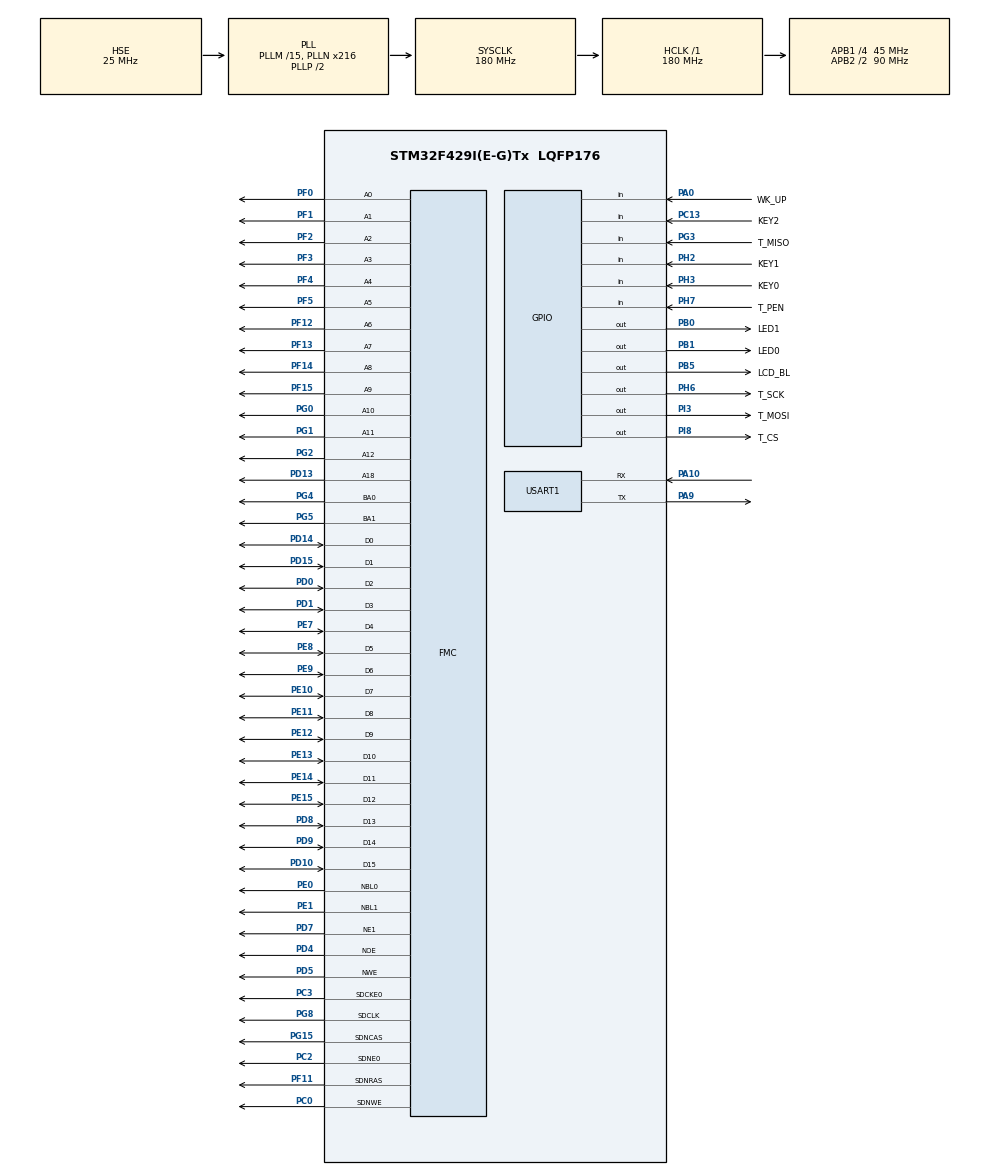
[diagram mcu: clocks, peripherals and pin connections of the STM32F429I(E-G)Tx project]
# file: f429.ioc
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FMC.BusTurnAroundDuration1=0
FMC.CASLatency1=FMC_SDRAM_CAS_LATENCY_3
FMC.ColumnBitsNumber1=FMC_SDRAM_COLUMN_BITS_NUM_9
FMC.DataSetupTime1=70
FMC.ExitSelfRefreshDelay1=8
FMC.ExtendedBusTurnAroundDuration1=0
FMC.ExtendedDataSetupTime1=15
FMC.ExtendedMode1=FMC_EXTENDED_MODE_ENABLE
FMC.LoadToActiveDelay1=2
FMC.RCDDelay1=2
FMC.RPDelay1=2
FMC.RPDelay2=2
FMC.ReadBurst1=FMC_SDRAM_RBURST_ENABLE
FMC.ReadBurst2=FMC_SDRAM_RBURST_ENABLE
FMC.ReadPipeDelay1=FMC_SDRAM_RPIPE_DELAY_1
FMC.ReadPipeDelay2=FMC_SDRAM_RPIPE_DELAY_1
FMC.RowCycleDelay1=6
FMC.RowCycleDelay2=6
FMC.SDClockPeriod1=FMC_SDRAM_CLOCK_PERIOD_2
FMC.SDClockPeriod2=FMC_SDRAM_CLOCK_PERIOD_2
FMC.SelfRefreshTime1=6
FMC.WriteRecoveryTime1=6
FREERTOS.Tasks01=defaultTask,24,128,StartDefaultTask,Default,NULL,Dynamic,NULL,NULL;guiTask,8,1024,guiStartTask,Default,NULL,Dynamic,NULL,NULL;commcTask,8,1024,commcStartTask,Default,NULL,Dynamic,NULL,NULL
Mcu.Family=STM32F4
Mcu.Name=STM32F429I(E-G)Tx
Mcu.Package=LQFP176
NVIC.PriorityGroup=NVIC_PRIORITYGROUP_4
NVIC.TIM1_UP_TIM10_IRQn=true\:15\:0\:false\:false\:true\:false\:false\:true\:true
NVIC.TimeBase=TIM1_UP_TIM10_IRQn
NVIC.TimeBaseIP=TIM1
NVIC.USART1_IRQn=true\:5\:0\:false\:false\:true\:true\:true\:true\:true
PA0/WKUP.GPIO_Label=WK_UP
PA0/WKUP.GPIO_PuPd=GPIO_PULLDOWN
PA0/WKUP.Signal=GPIO_Input
PA10.Mode=Asynchronous
PA10.Signal=USART1_RX
PA13.Mode=Serial_Wire
PA13.Signal=SYS_JTMS-SWDIO
PA14.Mode=Serial_Wire
PA14.Signal=SYS_JTCK-SWCLK
PA9.Mode=Asynchronous
PA9.Signal=USART1_TX
PB0.GPIO_Label=LED1
PB0.Signal=GPIO_Output
PB1.GPIO_Label=LED0
PB1.GPIO_PuPd=GPIO_PULLUP
PB1.Signal=GPIO_Output
PB5.GPIO_Label=LCD_BL
PB5.Signal=GPIO_Output
PC0.Signal=FMC_SDNWE
PC13.GPIO_Label=KEY2
PC13.GPIO_PuPd=GPIO_PULLUP
PC13.Signal=GPIO_Input
PC14/OSC32_IN.Mode=LSE-External-Oscillator
PC14/OSC32_IN.Signal=RCC_OSC32_IN
PC15/OSC32_OUT.Mode=LSE-External-Oscillator
PC15/OSC32_OUT.Signal=RCC_OSC32_OUT
PC2.Mode=SdramChipSelect1_1
PC2.Signal=FMC_SDNE0
PC3.Mode=SdramChipSelect1_1
PC3.Signal=FMC_SDCKE0
PD0.Signal=FMC_D2_DA2
PD1.Signal=FMC_D3_DA3
PD10.Signal=FMC_D15_DA15
PD13.Signal=FMC_A18
PD14.Signal=FMC_D0_DA0
PD15.Signal=FMC_D1_DA1
PD4.Signal=FMC_NOE
PD5.Signal=FMC_NWE
PD7.Mode=NorPsramChipSelect1_1
PD7.Signal=FMC_NE1
PD8.Signal=FMC_D13_DA13
PD9.Signal=FMC_D14_DA14
PE0.Signal=FMC_NBL0
PE1.Signal=FMC_NBL1
PE10.Signal=FMC_D7_DA7
PE11.Signal=FMC_D8_DA8
PE12.Signal=FMC_D9_DA9
PE13.Signal=FMC_D10_DA10
PE14.Signal=FMC_D11_DA11
PE15.Signal=FMC_D12_DA12
PE7.Signal=FMC_D4_DA4
PE8.Signal=FMC_D5_DA5
PE9.Signal=FMC_D6_DA6
PF0.Signal=FMC_A0
PF1.Signal=FMC_A1
PF11.Signal=FMC_SDNRAS
PF12.Signal=FMC_A6
PF13.Signal=FMC_A7
PF14.Signal=FMC_A8
PF15.Signal=FMC_A9
PF2.Signal=FMC_A2
PF3.Signal=FMC_A3
PF4.Signal=FMC_A4
PF5.Signal=FMC_A5
PG0.Signal=FMC_A10
PG1.Signal=FMC_A11
PG15.Signal=FMC_SDNCAS
PG2.Signal=FMC_A12
PG3.GPIO_Label=T_MISO
PG3.Signal=GPIO_Input
PG4.Signal=FMC_A14_BA0
PG5.Signal=FMC_A15_BA1
PG8.Signal=FMC_SDCLK
PH0/OSC_IN.Mode=HSE-External-Oscillator
PH0/OSC_IN.Signal=RCC_OSC_IN
PH1/OSC_OUT.Mode=HSE-External-Oscillator
PH1/OSC_OUT.Signal=RCC_OSC_OUT
PH2.GPIO_Label=KEY1
PH2.GPIO_PuPd=GPIO_PULLUP
PH2.Signal=GPIO_Input
PH3.GPIO_Label=KEY0
PH3.GPIO_PuPd=GPIO_PULLUP
PH3.Signal=GPIO_Input
PH6.GPIO_Label=T_SCK
PH6.GPIO_PuPd=GPIO_PULLUP
PH6.GPIO_Speed=GPIO_SPEED_FREQ_HIGH
PH6.Signal=GPIO_Output
PH7.GPIO_Label=T_PEN
PH7.Signal=GPIO_Input
PI3.GPIO_Label=T_MOSI
PI3.GPIO_PuPd=GPIO_PULLUP
PI3.GPIO_Speed=GPIO_SPEED_FREQ_HIGH
PI3.Signal=GPIO_Output
PI8.GPIO_Label=T_CS
PI8.GPIO_PuPd=GPIO_PULLUP
PI8.GPIO_Speed=GPIO_SPEED_FREQ_LOW
PI8.Signal=GPIO_Output
ProjectManager.HeapSize=0x8000
ProjectManager.StackSize=0x8000
ProjectManager.TargetToolchain=MDK-ARM V5.32
RCC.48MHZClocksFreq_Value=90000000
RCC.AHBFreq_Value=180000000
RCC.APB1CLKDivider=RCC_HCLK_DIV4
RCC.APB1Freq_Value=45000000
RCC.APB1TimFreq_Value=90000000
RCC.APB2CLKDivider=RCC_HCLK_DIV2
RCC.APB2Freq_Value=90000000
RCC.APB2TimFreq_Value=180000000
RCC.CortexFreq_Value=180000000
RCC.HCLKFreq_Value=180000000
RCC.HSE_VALUE=25000000
RCC.HSI_VALUE=16000000
RCC.PLLM=15
RCC.PLLN=216
RCC.PLLSourceVirtual=RCC_PLLSOURCE_HSE
RCC.SYSCLKFreq_VALUE=180000000
RCC.SYSCLKSource=RCC_SYSCLKSOURCE_PLLCLK
RCC.VCOOutputFreq_Value=360000000
SH.FMC_A0.0=FMC_A0,13b-sda1
SH.FMC_A1.0=FMC_A1,13b-sda1
SH.FMC_A10.0=FMC_A10,13b-sda1
SH.FMC_A11.0=FMC_A11,13b-sda1
SH.FMC_A12.0=FMC_A12,13b-sda1
SH.FMC_A14_BA0.0=FMC_BA0,FourSdramBanks1
SH.FMC_A15_BA1.0=FMC_BA1,FourSdramBanks1
SH.FMC_A18.0=FMC_A18,A18_1
SH.FMC_A2.0=FMC_A2,13b-sda1
SH.FMC_A3.0=FMC_A3,13b-sda1
SH.FMC_A4.0=FMC_A4,13b-sda1
SH.FMC_A5.0=FMC_A5,13b-sda1
SH.FMC_A6.0=FMC_A6,13b-sda1
SH.FMC_A7.0=FMC_A7,13b-sda1
SH.FMC_A8.0=FMC_A8,13b-sda1
SH.FMC_A9.0=FMC_A9,13b-sda1
SH.FMC_D0_DA0.0=FMC_D0,16b-d1
SH.FMC_D0_DA0.1=FMC_D0,sd-16b-d1
SH.FMC_D10_DA10.0=FMC_D10,16b-d1
SH.FMC_D10_DA10.1=FMC_D10,sd-16b-d1
SH.FMC_D11_DA11.0=FMC_D11,16b-d1
SH.FMC_D11_DA11.1=FMC_D11,sd-16b-d1
SH.FMC_D12_DA12.0=FMC_D12,16b-d1
SH.FMC_D12_DA12.1=FMC_D12,sd-16b-d1
SH.FMC_D13_DA13.0=FMC_D13,16b-d1
SH.FMC_D13_DA13.1=FMC_D13,sd-16b-d1
SH.FMC_D14_DA14.0=FMC_D14,16b-d1
SH.FMC_D14_DA14.1=FMC_D14,sd-16b-d1
SH.FMC_D15_DA15.0=FMC_D15,16b-d1
SH.FMC_D15_DA15.1=FMC_D15,sd-16b-d1
SH.FMC_D1_DA1.0=FMC_D1,16b-d1
SH.FMC_D1_DA1.1=FMC_D1,sd-16b-d1
SH.FMC_D2_DA2.0=FMC_D2,16b-d1
SH.FMC_D2_DA2.1=FMC_D2,sd-16b-d1
SH.FMC_D3_DA3.0=FMC_D3,16b-d1
SH.FMC_D3_DA3.1=FMC_D3,sd-16b-d1
SH.FMC_D4_DA4.0=FMC_D4,16b-d1
SH.FMC_D4_DA4.1=FMC_D4,sd-16b-d1
SH.FMC_D5_DA5.0=FMC_D5,16b-d1
SH.FMC_D5_DA5.1=FMC_D5,sd-16b-d1
SH.FMC_D6_DA6.0=FMC_D6,16b-d1
SH.FMC_D6_DA6.1=FMC_D6,sd-16b-d1
SH.FMC_D7_DA7.0=FMC_D7,16b-d1
SH.FMC_D7_DA7.1=FMC_D7,sd-16b-d1
SH.FMC_D8_DA8.0=FMC_D8,16b-d1
SH.FMC_D8_DA8.1=FMC_D8,sd-16b-d1
SH.FMC_D9_DA9.0=FMC_D9,16b-d1
SH.FMC_D9_DA9.1=FMC_D9,sd-16b-d1
SH.FMC_NBL0.0=FMC_NBL0,Sd2ByteEnable1
SH.FMC_NBL1.0=FMC_NBL1,Sd2ByteEnable1
SH.FMC_NOE.0=FMC_NOE,Lcd1
SH.FMC_NWE.0=FMC_NWE,Lcd1
SH.FMC_SDCLK.0=FMC_SDCLK,13b-sda1
SH.FMC_SDNCAS.0=FMC_SDNCAS,13b-sda1
SH.FMC_SDNRAS.0=FMC_SDNRAS,13b-sda1
SH.FMC_SDNWE.0=FMC_SDNWE,13b-sda1
TIM6.Prescaler=90-1
USART1.VirtualMode=VM_ASYNC
VP_FREERTOS_VS_CMSIS_V2.Mode=CMSIS_V2
VP_SYS_VS_tim1.Mode=TIM1
VP_TIM6_VS_ClockSourceINT.Mode=Enable_Timer
board=custom

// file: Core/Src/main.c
/* USER CODE BEGIN Header */
/**
  ******************************************************************************
  * @file           : main.c
  * @brief          : Main program body
  ******************************************************************************
  * @attention
  *
  * Copyright (c) 2023 STMicroelectronics.
  * All rights reserved.
  *
  * This software is licensed under terms that can be found in the LICENSE file
  * in the root directory of this software component.
  * If no LICENSE file comes with this software, it is provided AS-IS.
  *
  ******************************************************************************
  */
/* USER CODE END Header */
#include "main.h"
#include "cmsis_os.h"
#include "tim.h"
#include "usart.h"
#include "gpio.h"
#include "fmc.h"

void SystemClock_Config(void);
void MX_FREERTOS_Init(void);

int main(void)
{

  /* MCU Configuration--------------------------------------------------------*/

  /* Reset of all peripherals, Initializes the Flash interface and the Systick. */
  HAL_Init();

  /* Configure the system clock */
  SystemClock_Config();

  /* Initialize all configured peripherals */
  MX_GPIO_Init();
  MX_USART1_UART_Init();
  MX_FMC_Init();
  MX_TIM6_Init();
  /* USER CODE BEGIN 2 */
  LED0_OFF;
  LED1_OFF;
  /* USER CODE END 2 */

  /* Init scheduler */
  osKernelInitialize();  /* Call init function for freertos objects (in freertos.c) */
  MX_FREERTOS_Init();

  /* Start scheduler */
  osKernelStart();

  /* We should never get here as control is now taken by the scheduler */
  /* Infinite loop */
  while (1)
  {

  }
}

void SystemClock_Config(void)
{
  RCC_OscInitTypeDef RCC_OscInitStruct = {0};
  RCC_ClkInitTypeDef RCC_ClkInitStruct = {0};

  /** Configure the main internal regulator output voltage
  */
  __HAL_RCC_PWR_CLK_ENABLE();
  __HAL_PWR_VOLTAGESCALING_CONFIG(PWR_REGULATOR_VOLTAGE_SCALE1);

  /** Initializes the RCC Oscillators according to the specified parameters
  * in the RCC_OscInitTypeDef structure.
  */
  RCC_OscInitStruct.OscillatorType = RCC_OSCILLATORTYPE_HSE;
  RCC_OscInitStruct.HSEState = RCC_HSE_ON;
  RCC_OscInitStruct.PLL.PLLState = RCC_PLL_ON;
  RCC_OscInitStruct.PLL.PLLSource = RCC_PLLSOURCE_HSE;
  RCC_OscInitStruct.PLL.PLLM = 15;
  RCC_OscInitStruct.PLL.PLLN = 216;
  RCC_OscInitStruct.PLL.PLLP = RCC_PLLP_DIV2;
  RCC_OscInitStruct.PLL.PLLQ = 4;
  if (HAL_RCC_OscConfig(&RCC_OscInitStruct) != HAL_OK)
  {
    Error_Handler();
  }

  /** Activate the Over-Drive mode
  */
  if (HAL_PWREx_EnableOverDrive() != HAL_OK)
  {
    Error_Handler();
  }

  /** Initializes the CPU, AHB and APB buses clocks
  */
  RCC_ClkInitStruct.ClockType = RCC_CLOCKTYPE_HCLK|RCC_CLOCKTYPE_SYSCLK
                              |RCC_CLOCKTYPE_PCLK1|RCC_CLOCKTYPE_PCLK2;
  RCC_ClkInitStruct.SYSCLKSource = RCC_SYSCLKSOURCE_PLLCLK;
  RCC_ClkInitStruct.AHBCLKDivider = RCC_SYSCLK_DIV1;
  RCC_ClkInitStruct.APB1CLKDivider = RCC_HCLK_DIV4;
  RCC_ClkInitStruct.APB2CLKDivider = RCC_HCLK_DIV2;

  if (HAL_RCC_ClockConfig(&RCC_ClkInitStruct, FLASH_LATENCY_5) != HAL_OK)
  {
    Error_Handler();
  }
}

void HAL_TIM_PeriodElapsedCallback(TIM_HandleTypeDef *htim)
{
  /* USER CODE BEGIN Callback 0 */
  lv_tick_inc(1);
  /* USER CODE END Callback 0 */
  if (htim->Instance == TIM1) {
    HAL_IncTick();
  }
}

void Error_Handler(void)
{
  __disable_irq();
  while (1)
  {
  }
}

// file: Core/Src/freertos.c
/* USER CODE BEGIN Header */
/**
  ******************************************************************************
  * File Name          : freertos.c
  * Description        : Code for freertos applications
  ******************************************************************************
  * @attention
  *
  * Copyright (c) 2023 STMicroelectronics.
  * All rights reserved.
  *
  * This software is licensed under terms that can be found in the LICENSE file
  * in the root directory of this software component.
  * If no LICENSE file comes with this software, it is provided AS-IS.
  *
  ******************************************************************************
  */
/* USER CODE END Header */

#include "FreeRTOS.h"
#include "task.h"
#include "main.h"
#include "cmsis_os.h"

/* USER CODE BEGIN Includes */
#include "my_code_init.h"
/* USER CODE END Includes */

/* Definitions for defaultTask */
osThreadId_t defaultTaskHandle;
const osThreadAttr_t defaultTask_attributes = {
  .name = "defaultTask",
  .stack_size = 128 * 4,
  .priority = (osPriority_t) osPriorityNormal,
};
/* Definitions for guiTask */
osThreadId_t guiTaskHandle;
const osThreadAttr_t guiTask_attributes = {
  .name = "guiTask",
  .stack_size = 1024 * 4,
  .priority = (osPriority_t) osPriorityLow,
};
/* Definitions for commcTask */
osThreadId_t commcTaskHandle;
const osThreadAttr_t commcTask_attributes = {
  .name = "commcTask",
  .stack_size = 1024 * 4,
  .priority = (osPriority_t) osPriorityLow,
};

void StartDefaultTask(void *argument);
void guiStartTask(void *argument);
void commcStartTask(void *argument);

void MX_FREERTOS_Init(void); /* (MISRA C 2004 rule 8.1) */

void MX_FREERTOS_Init(void) {
  /* USER CODE BEGIN Init */
  my_code_init();
  my_gui_entry();
  /* USER CODE END Init */

  /* Create the thread(s) */
  /* creation of defaultTask */
  defaultTaskHandle = osThreadNew(StartDefaultTask, NULL, &defaultTask_attributes);

  /* creation of guiTask */
  guiTaskHandle = osThreadNew(guiStartTask, NULL, &guiTask_attributes);

  /* creation of commcTask */
  commcTaskHandle = osThreadNew(commcStartTask, NULL, &commcTask_attributes);

}

void StartDefaultTask(void *argument)
{
  /* USER CODE BEGIN StartDefaultTask */
  /* Infinite loop */
  for(;;)
  {
    LED0_TRG;
    osDelay(1000);
  }
  /* USER CODE END StartDefaultTask */
}

void guiStartTask(void *argument)
{
  /* USER CODE BEGIN guiStartTask */
  /* Infinite loop */
  for(;;)
  {
    lv_timer_handler();
    osDelay(1);
  }
  /* USER CODE END guiStartTask */
}

void commcStartTask(void *argument)
{
  /* USER CODE BEGIN commcStartTask */
  /* Infinite loop */
  for(;;)
  {
    // my_commc_loop();
    osDelay(1);
  }
  /* USER CODE END commcStartTask */
}
